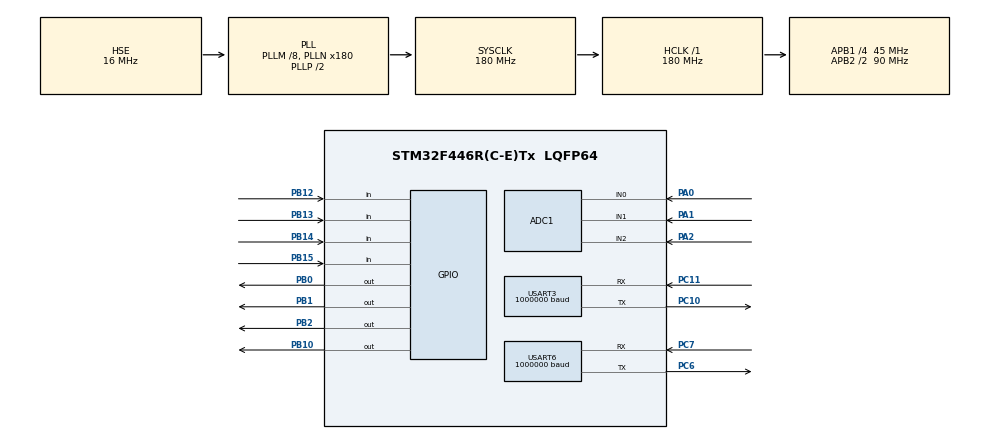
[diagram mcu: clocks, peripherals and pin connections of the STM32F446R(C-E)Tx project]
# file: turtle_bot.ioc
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ADC1.Channel-0\#ChannelRegularConversion=ADC_CHANNEL_0
ADC1.Channel-1\#ChannelRegularConversion=ADC_CHANNEL_0
ADC1.Channel-2\#ChannelRegularConversion=ADC_CHANNEL_0
ADC1.DMAContinuousRequests=ENABLE
ADC1.ExternalTrigConv=ADC_EXTERNALTRIGCONV_T8_TRGO
ADC1.NbrOfConversion=3
ADC1.NbrOfConversionFlag=1
ADC1.Rank-0\#ChannelRegularConversion=1
ADC1.Rank-1\#ChannelRegularConversion=2
ADC1.Rank-2\#ChannelRegularConversion=3
ADC1.SamplingTime-0\#ChannelRegularConversion=ADC_SAMPLETIME_15CYCLES
ADC1.SamplingTime-1\#ChannelRegularConversion=ADC_SAMPLETIME_15CYCLES
ADC1.SamplingTime-2\#ChannelRegularConversion=ADC_SAMPLETIME_15CYCLES
ADC1.ScanConvMode=ENABLE
ADC1.master=1
Dma.ADC1.0.Direction=DMA_PERIPH_TO_MEMORY
Dma.ADC1.0.FIFOMode=DMA_FIFOMODE_DISABLE
Dma.ADC1.0.Instance=DMA2_Stream0
Dma.ADC1.0.MemDataAlignment=DMA_MDATAALIGN_WORD
Dma.ADC1.0.MemInc=DMA_MINC_ENABLE
Dma.ADC1.0.Mode=DMA_CIRCULAR
Dma.ADC1.0.PeriphDataAlignment=DMA_PDATAALIGN_WORD
Dma.ADC1.0.PeriphInc=DMA_PINC_DISABLE
Dma.ADC1.0.Priority=DMA_PRIORITY_LOW
Dma.Request0=ADC1
Dma.Request1=USART3_RX
Dma.Request2=USART6_RX
Dma.USART3_RX.1.Direction=DMA_PERIPH_TO_MEMORY
Dma.USART3_RX.1.FIFOMode=DMA_FIFOMODE_DISABLE
Dma.USART3_RX.1.Instance=DMA1_Stream1
Dma.USART3_RX.1.MemDataAlignment=DMA_MDATAALIGN_BYTE
Dma.USART3_RX.1.MemInc=DMA_MINC_ENABLE
Dma.USART3_RX.1.Mode=DMA_CIRCULAR
Dma.USART3_RX.1.PeriphDataAlignment=DMA_PDATAALIGN_BYTE
Dma.USART3_RX.1.PeriphInc=DMA_PINC_DISABLE
Dma.USART3_RX.1.Priority=DMA_PRIORITY_LOW
Dma.USART6_RX.2.Direction=DMA_PERIPH_TO_MEMORY
Dma.USART6_RX.2.FIFOMode=DMA_FIFOMODE_DISABLE
Dma.USART6_RX.2.Instance=DMA2_Stream1
Dma.USART6_RX.2.MemDataAlignment=DMA_MDATAALIGN_BYTE
Dma.USART6_RX.2.MemInc=DMA_MINC_ENABLE
Dma.USART6_RX.2.Mode=DMA_CIRCULAR
Dma.USART6_RX.2.PeriphDataAlignment=DMA_PDATAALIGN_BYTE
Dma.USART6_RX.2.PeriphInc=DMA_PINC_DISABLE
Dma.USART6_RX.2.Priority=DMA_PRIORITY_LOW
Mcu.Family=STM32F4
Mcu.Name=STM32F446R(C-E)Tx
Mcu.Package=LQFP64
NVIC.ADC_IRQn=true\:0\:0\:false\:false\:true\:true\:true\:true
NVIC.DMA1_Stream1_IRQn=true\:0\:0\:false\:false\:true\:false\:true\:true
NVIC.DMA2_Stream0_IRQn=true\:0\:0\:false\:false\:true\:false\:true\:true
NVIC.DMA2_Stream1_IRQn=true\:0\:0\:false\:false\:true\:false\:true\:true
NVIC.PriorityGroup=NVIC_PRIORITYGROUP_4
NVIC.TIM1_UP_TIM10_IRQn=true\:0\:0\:false\:false\:true\:true\:true\:true
NVIC.TIM8_UP_TIM13_IRQn=true\:0\:0\:false\:false\:true\:true\:true\:true
NVIC.USART3_IRQn=true\:0\:0\:false\:false\:true\:true\:true\:true
NVIC.USART6_IRQn=true\:0\:0\:false\:false\:true\:true\:true\:true
PA0-WKUP.Signal=ADCx_IN0
PA1.Signal=ADCx_IN1
PA13.Mode=Serial_Wire
PA13.Signal=SYS_JTMS-SWDIO
PA14.Mode=Serial_Wire
PA14.Signal=SYS_JTCK-SWCLK
PA2.Signal=ADCx_IN2
PB0.Signal=GPIO_Output
PB1.Signal=GPIO_Output
PB10.Signal=GPIO_Output
PB12.Signal=GPIO_Input
PB13.Signal=GPIO_Input
PB14.Signal=GPIO_Input
PB15.Signal=GPIO_Input
PB2.Signal=GPIO_Output
PC10.Mode=Asynchronous
PC10.Signal=USART3_TX
PC11.Mode=Asynchronous
PC11.Signal=USART3_RX
PC6.Mode=Asynchronous
PC6.Signal=USART6_TX
PC7.Mode=Asynchronous
PC7.Signal=USART6_RX
PH0-OSC_IN.Mode=HSE-External-Oscillator
PH0-OSC_IN.Signal=RCC_OSC_IN
PH1-OSC_OUT.Mode=HSE-External-Oscillator
PH1-OSC_OUT.Signal=RCC_OSC_OUT
ProjectManager.HeapSize=0x200
ProjectManager.StackSize=0x400
ProjectManager.TargetToolchain=STM32CubeIDE
RCC.AHBFreq_Value=180000000
RCC.APB1CLKDivider=RCC_HCLK_DIV4
RCC.APB1Freq_Value=45000000
RCC.APB1TimFreq_Value=90000000
RCC.APB2CLKDivider=RCC_HCLK_DIV2
RCC.APB2Freq_Value=90000000
RCC.APB2TimFreq_Value=180000000
RCC.CortexFreq_Value=180000000
RCC.HCLKFreq_Value=180000000
RCC.HSE_VALUE=16000000
RCC.PLLM=8
RCC.PLLN=180
RCC.PLLSourceVirtual=RCC_PLLSOURCE_HSE
RCC.SYSCLKFreq_VALUE=180000000
RCC.SYSCLKSource=RCC_SYSCLKSOURCE_PLLCLK
RCC.USBFreq_Value=180000000
RCC.VCOOutputFreq_Value=360000000
SH.ADCx_IN0.0=ADC1_IN0,IN0
SH.ADCx_IN1.0=ADC1_IN1,IN1
SH.ADCx_IN2.0=ADC1_IN2,IN2
TIM1.Period=10000-1
TIM1.Prescaler=18-1
TIM1.TIM_MasterOutputTrigger=TIM_TRGO_UPDATE
TIM8.Period=10000-1
TIM8.Prescaler=180-1
TIM8.TIM_MasterOutputTrigger=TIM_TRGO_UPDATE
USART3.BaudRate=1000000
USART3.VirtualMode=VM_ASYNC
USART6.BaudRate=1000000
USART6.VirtualMode=VM_ASYNC
VP_TIM1_VS_ClockSourceINT.Mode=Internal
VP_TIM8_VS_ClockSourceINT.Mode=Internal
board=custom

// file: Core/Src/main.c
/* USER CODE BEGIN Header */
/**
  ******************************************************************************
  * @file           : main.c
  * @brief          : Main program body
  ******************************************************************************
  * @attention
  *
  * Copyright (c) 2026 STMicroelectronics.
  * All rights reserved.
  *
  * This software is licensed under terms that can be found in the LICENSE file
  * in the root directory of this software component.
  * If no LICENSE file comes with this software, it is provided AS-IS.
  *
  ******************************************************************************
  */
/* USER CODE END Header */
#include "main.h"
#include "adc.h"
#include "dma.h"
#include "tim.h"
#include "usart.h"
#include "gpio.h"

/* USER CODE BEGIN Includes */
#include "turtle_bot.h"
/* USER CODE END Includes */

/* USER CODE BEGIN PV */
int written_vel[2], read_vel[2], read_adc_val[3];
/* USER CODE END PV */

void SystemClock_Config(void);

int main(void)
{

  /* MCU Configuration--------------------------------------------------------*/

  /* Reset of all peripherals, Initializes the Flash interface and the Systick. */
  HAL_Init();

  /* Configure the system clock */
  SystemClock_Config();

  /* Initialize all configured peripherals */
  MX_GPIO_Init();
  MX_DMA_Init();
  MX_USART3_UART_Init();
  MX_USART6_UART_Init();
  MX_ADC1_Init();
  MX_TIM1_Init();
  MX_TIM8_Init();
  /* USER CODE BEGIN 2 */
  tb_init(written_vel, read_vel, read_adc_val);
  tb_start();
  /* USER CODE END 2 */

  /* Infinite loop */
  while (1)
  {

	/* USER CODE BEGIN 3 */
	  tb_process();
  }
  /* USER CODE END 3 */
}

void SystemClock_Config(void)
{
  RCC_OscInitTypeDef RCC_OscInitStruct = {0};
  RCC_ClkInitTypeDef RCC_ClkInitStruct = {0};

  /** Configure the main internal regulator output voltage
  */
  __HAL_RCC_PWR_CLK_ENABLE();
  __HAL_PWR_VOLTAGESCALING_CONFIG(PWR_REGULATOR_VOLTAGE_SCALE1);

  /** Initializes the RCC Oscillators according to the specified parameters
  * in the RCC_OscInitTypeDef structure.
  */
  RCC_OscInitStruct.OscillatorType = RCC_OSCILLATORTYPE_HSE;
  RCC_OscInitStruct.HSEState = RCC_HSE_ON;
  RCC_OscInitStruct.PLL.PLLState = RCC_PLL_ON;
  RCC_OscInitStruct.PLL.PLLSource = RCC_PLLSOURCE_HSE;
  RCC_OscInitStruct.PLL.PLLM = 8;
  RCC_OscInitStruct.PLL.PLLN = 180;
  RCC_OscInitStruct.PLL.PLLP = RCC_PLLP_DIV2;
  RCC_OscInitStruct.PLL.PLLQ = 2;
  RCC_OscInitStruct.PLL.PLLR = 2;
  if (HAL_RCC_OscConfig(&RCC_OscInitStruct) != HAL_OK)
  {
    Error_Handler();
  }

  /** Activate the Over-Drive mode
  */
  if (HAL_PWREx_EnableOverDrive() != HAL_OK)
  {
    Error_Handler();
  }

  /** Initializes the CPU, AHB and APB buses clocks
  */
  RCC_ClkInitStruct.ClockType = RCC_CLOCKTYPE_HCLK|RCC_CLOCKTYPE_SYSCLK
                              |RCC_CLOCKTYPE_PCLK1|RCC_CLOCKTYPE_PCLK2;
  RCC_ClkInitStruct.SYSCLKSource = RCC_SYSCLKSOURCE_PLLCLK;
  RCC_ClkInitStruct.AHBCLKDivider = RCC_SYSCLK_DIV1;
  RCC_ClkInitStruct.APB1CLKDivider = RCC_HCLK_DIV4;
  RCC_ClkInitStruct.APB2CLKDivider = RCC_HCLK_DIV2;

  if (HAL_RCC_ClockConfig(&RCC_ClkInitStruct, FLASH_LATENCY_5) != HAL_OK)
  {
    Error_Handler();
  }
}

void Error_Handler(void)
{
  __disable_irq();
  while (1)
  {
  }
}
